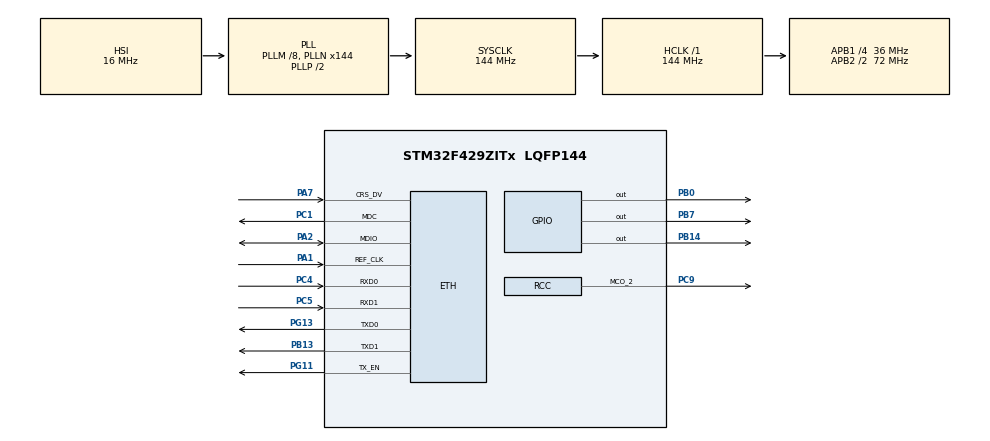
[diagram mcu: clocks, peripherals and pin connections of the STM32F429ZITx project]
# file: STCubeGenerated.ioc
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ETH.AutoNegotiation=ETH_AUTONEGOTIATION_DISABLE
ETH.ChecksumMode=ETH_CHECKSUM_BY_HARDWARE
ETH.MediaInterface=ETH_MEDIA_INTERFACE_RMII
ETH.PhyAddress=0
ETH.RxMode=ETH_RXPOLLING_MODE
LWIP.CHECKSUM_BY_HARDWARE=1
LWIP.CHECKSUM_CHECK_ICMP=0
LWIP.CHECKSUM_CHECK_IP=0
LWIP.CHECKSUM_CHECK_TCP=0
LWIP.CHECKSUM_CHECK_UDP=0
LWIP.CHECKSUM_GEN_ICMP=0
LWIP.CHECKSUM_GEN_IP=0
LWIP.CHECKSUM_GEN_TCP=0
LWIP.CHECKSUM_GEN_UDP=0
LWIP.GATEWAY_ADDRESS=192.168.001.001
LWIP.HTTPD_USE_CUSTOM_FSDATA=1
LWIP.IP_ADDRESS=192.168.001.100
LWIP.LWIP_CHECKSUM_CTRL_PER_NETIF=0
LWIP.LWIP_CHECKSUM_ON_COPY=0
LWIP.LWIP_DBG_MIN_LEVEL=LWIP_DBG_MASK_LEVEL
LWIP.LWIP_DHCP=0
LWIP.LWIP_HTTPD=1
LWIP.LWIP_HTTPD_CUSTOM_FILES=1
LWIP.MEMP_NUM_PBUF=20
LWIP.MEMP_NUM_RAW_PCB=20
LWIP.MEMP_NUM_TCP_PCB_LISTEN=0
LWIP.MEMP_NUM_TCP_SEG=25
LWIP.MEM_SIZE=62000
LWIP.NETMASK_ADDRESS=255.255.255.000
LWIP.PBUF_POOL_BUFSIZE=592
LWIP.PBUF_POOL_SIZE=16
LWIP.TCP_MSS=536
LWIP.TCP_SND_BUF=4288
LWIP.TCP_SND_QUEUELEN=16
LWIP.TCP_WND=5144
LWIP.Version=v2.0.3_Cube
Mcu.Family=STM32F4
Mcu.Name=STM32F429ZITx
Mcu.Package=LQFP144
NVIC.PriorityGroup=NVIC_PRIORITYGROUP_4
NVIC.TIM6_DAC_IRQn=true\:8\:0\:true\:false\:true\:true\:true
NVIC.TIM7_IRQn=true\:6\:0\:true\:false\:true\:true\:true
PA1.Mode=RMII
PA1.Signal=ETH_REF_CLK
PA2.Mode=RMII
PA2.Signal=ETH_MDIO
PA7.Mode=RMII
PA7.Signal=ETH_CRS_DV
PB0.Signal=GPIO_Output
PB13.Mode=RMII
PB13.Signal=ETH_TXD1
PB14.Signal=GPIO_Output
PB7.Signal=GPIO_Output
PC1.Mode=RMII
PC1.Signal=ETH_MDC
PC4.Mode=RMII
PC4.Signal=ETH_RXD0
PC5.Mode=RMII
PC5.Signal=ETH_RXD1
PC9.GPIO_Speed=GPIO_SPEED_FREQ_VERY_HIGH
PC9.Mode=Clock-out-2
PC9.Signal=RCC_MCO_2
PG11.Mode=RMII
PG11.Signal=ETH_TX_EN
PG13.Mode=RMII
PG13.Signal=ETH_TXD0
ProjectManager.HeapSize=0x8000
ProjectManager.StackSize=0x2000
ProjectManager.TargetToolchain=Makefile
RCC.48MHZClocksFreq_Value=72000000
RCC.AHBFreq_Value=144000000
RCC.APB1CLKDivider=RCC_HCLK_DIV4
RCC.APB1Freq_Value=36000000
RCC.APB1TimFreq_Value=72000000
RCC.APB2CLKDivider=RCC_HCLK_DIV2
RCC.APB2Freq_Value=72000000
RCC.APB2TimFreq_Value=144000000
RCC.CortexFreq_Value=144000000
RCC.HCLKFreq_Value=144000000
RCC.HSE_VALUE=25000000
RCC.HSI_VALUE=16000000
RCC.LSE_VALUE=32768
RCC.PLLM=8
RCC.PLLN=144
RCC.RCC_MCODiv2=RCC_MCODIV_2
RCC.SYSCLKFreq_VALUE=144000000
RCC.SYSCLKSource=RCC_SYSCLKSOURCE_PLLCLK
RCC.VCOOutputFreq_Value=288000000
TIM6.Period=10000
TIM6.Prescaler=9000
TIM7.Period=30
TIM7.Prescaler=700
VP_LWIP_VS_Enabled.Mode=Enabled
VP_TIM6_VS_ClockSourceINT.Mode=Enable_Timer
VP_TIM7_VS_ClockSourceINT.Mode=Enable_Timer
board=custom

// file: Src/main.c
/* USER CODE BEGIN Header */
/**
  ******************************************************************************
  * @file           : main.c
  * @brief          : Main program body
  ******************************************************************************
  * @attention
  *
  * <h2><center>&copy; Copyright (c) 2019 STMicroelectronics.
  * All rights reserved.</center></h2>
  *
  * This software component is licensed by ST under BSD 3-Clause license,
  * the "License"; You may not use this file except in compliance with the
  * License. You may obtain a copy of the License at:
  *                        opensource.org/licenses/BSD-3-Clause
  *
  ******************************************************************************
  */
/* USER CODE END Header */

#include "main.h"
#include "lwip.h"

/* USER CODE BEGIN Includes */
#include "stm32f429xx.h"
#include "fsdata_custom.h"
#include "user_code.h"
/* USER CODE END Includes */

TIM_HandleTypeDef htim6;
TIM_HandleTypeDef htim7;

void SystemClock_Config(void);
static void MX_GPIO_Init(void);
static void MX_TIM6_Init(void);
static void MX_TIM7_Init(void);

int main(void)
{

  /* MCU Configuration--------------------------------------------------------*/

  /* Reset of all peripherals, Initializes the Flash interface and the Systick. */
  HAL_Init();

  /* Configure the system clock */
  SystemClock_Config();

  /* Initialize all configured peripherals */
  MX_GPIO_Init();
  MX_TIM6_Init();
  MX_LWIP_Init();
  MX_TIM7_Init();
  /* USER CODE BEGIN 2 */
	tcpAcq_init();
  generateData();
  /* USER CODE END 2 */

  /* Infinite loop */
	while (1)
  {

  }
}

void SystemClock_Config(void)
{
  RCC_OscInitTypeDef RCC_OscInitStruct = {0};
  RCC_ClkInitTypeDef RCC_ClkInitStruct = {0};

  /** Configure the main internal regulator output voltage
  */
  __HAL_RCC_PWR_CLK_ENABLE();
  __HAL_PWR_VOLTAGESCALING_CONFIG(PWR_REGULATOR_VOLTAGE_SCALE1);
  /** Initializes the CPU, AHB and APB busses clocks
  */
  RCC_OscInitStruct.OscillatorType = RCC_OSCILLATORTYPE_HSI;
  RCC_OscInitStruct.HSIState = RCC_HSI_ON;
  RCC_OscInitStruct.HSICalibrationValue = RCC_HSICALIBRATION_DEFAULT;
  RCC_OscInitStruct.PLL.PLLState = RCC_PLL_ON;
  RCC_OscInitStruct.PLL.PLLSource = RCC_PLLSOURCE_HSI;
  RCC_OscInitStruct.PLL.PLLM = 8;
  RCC_OscInitStruct.PLL.PLLN = 144;
  RCC_OscInitStruct.PLL.PLLP = RCC_PLLP_DIV2;
  RCC_OscInitStruct.PLL.PLLQ = 4;
  if (HAL_RCC_OscConfig(&RCC_OscInitStruct) != HAL_OK)
  {
    Error_Handler();
  }
  /** Initializes the CPU, AHB and APB busses clocks
  */
  RCC_ClkInitStruct.ClockType = RCC_CLOCKTYPE_HCLK|RCC_CLOCKTYPE_SYSCLK
                              |RCC_CLOCKTYPE_PCLK1|RCC_CLOCKTYPE_PCLK2;
  RCC_ClkInitStruct.SYSCLKSource = RCC_SYSCLKSOURCE_PLLCLK;
  RCC_ClkInitStruct.AHBCLKDivider = RCC_SYSCLK_DIV1;
  RCC_ClkInitStruct.APB1CLKDivider = RCC_HCLK_DIV4;
  RCC_ClkInitStruct.APB2CLKDivider = RCC_HCLK_DIV2;

  if (HAL_RCC_ClockConfig(&RCC_ClkInitStruct, FLASH_LATENCY_4) != HAL_OK)
  {
    Error_Handler();
  }
  HAL_RCC_MCOConfig(RCC_MCO2, RCC_MCO2SOURCE_SYSCLK, RCC_MCODIV_2);
}

static void MX_TIM6_Init(void)
{

  TIM_MasterConfigTypeDef sMasterConfig = {0};

  htim6.Instance = TIM6;
  htim6.Init.Prescaler = 9000;
  htim6.Init.CounterMode = TIM_COUNTERMODE_UP;
  htim6.Init.Period = 10000;
  htim6.Init.AutoReloadPreload = TIM_AUTORELOAD_PRELOAD_DISABLE;
  if (HAL_TIM_Base_Init(&htim6) != HAL_OK)
  {
    Error_Handler();
  }
  sMasterConfig.MasterOutputTrigger = TIM_TRGO_RESET;
  sMasterConfig.MasterSlaveMode = TIM_MASTERSLAVEMODE_DISABLE;
  if (HAL_TIMEx_MasterConfigSynchronization(&htim6, &sMasterConfig) != HAL_OK)
  {
    Error_Handler();
  }
  /* USER CODE BEGIN TIM6_Init 2 */
	if (HAL_TIM_Base_Start_IT(&htim6) != HAL_OK) {
		Error_Handler();
	}
  /* USER CODE END TIM6_Init 2 */

}

static void MX_TIM7_Init(void)
{

  TIM_MasterConfigTypeDef sMasterConfig = {0};

  htim7.Instance = TIM7;
  htim7.Init.Prescaler = 700;
  htim7.Init.CounterMode = TIM_COUNTERMODE_UP;
  htim7.Init.Period = 30;
  htim7.Init.AutoReloadPreload = TIM_AUTORELOAD_PRELOAD_DISABLE;
  if (HAL_TIM_Base_Init(&htim7) != HAL_OK)
  {
    Error_Handler();
  }
  sMasterConfig.MasterOutputTrigger = TIM_TRGO_RESET;
  sMasterConfig.MasterSlaveMode = TIM_MASTERSLAVEMODE_DISABLE;
  if (HAL_TIMEx_MasterConfigSynchronization(&htim7, &sMasterConfig) != HAL_OK)
  {
    Error_Handler();
  }
  /* USER CODE BEGIN TIM7_Init 2 */
	if (HAL_TIM_Base_Start_IT(&htim7) != HAL_OK) {
		Error_Handler();
	}
  /* USER CODE END TIM7_Init 2 */

}

static void MX_GPIO_Init(void)
{
  GPIO_InitTypeDef GPIO_InitStruct = {0};

  /* GPIO Ports Clock Enable */
  __HAL_RCC_GPIOC_CLK_ENABLE();
  __HAL_RCC_GPIOA_CLK_ENABLE();
  __HAL_RCC_GPIOB_CLK_ENABLE();
  __HAL_RCC_GPIOG_CLK_ENABLE();

  /*Configure GPIO pin Output Level */
  HAL_GPIO_WritePin(GPIOB, GPIO_PIN_0|GPIO_PIN_14|GPIO_PIN_7, GPIO_PIN_RESET);

  /*Configure GPIO pins : PB0 PB14 PB7 */
  GPIO_InitStruct.Pin = GPIO_PIN_0|GPIO_PIN_14|GPIO_PIN_7;
  GPIO_InitStruct.Mode = GPIO_MODE_OUTPUT_PP;
  GPIO_InitStruct.Pull = GPIO_NOPULL;
  GPIO_InitStruct.Speed = GPIO_SPEED_FREQ_LOW;
  HAL_GPIO_Init(GPIOB, &GPIO_InitStruct);

  /*Configure GPIO pin : PC9 */
  GPIO_InitStruct.Pin = GPIO_PIN_9;
  GPIO_InitStruct.Mode = GPIO_MODE_AF_PP;
  GPIO_InitStruct.Pull = GPIO_NOPULL;
  GPIO_InitStruct.Speed = GPIO_SPEED_FREQ_VERY_HIGH;
  GPIO_InitStruct.Alternate = GPIO_AF0_MCO;
  HAL_GPIO_Init(GPIOC, &GPIO_InitStruct);

}

void Error_Handler(void)
{
  /* USER CODE BEGIN Error_Handler_Debug */
  /* User can add his own implementation to report the HAL error return state */
	while (1) {
		HAL_GPIO_WritePin(GPIOB, GPIO_PIN_0 | GPIO_PIN_7 | GPIO_PIN_14, GPIO_PIN_SET);
	}
  /* USER CODE END Error_Handler_Debug */
}

/************************ (C) COPYRIGHT STMicroelectronics *****END OF FILE****/
